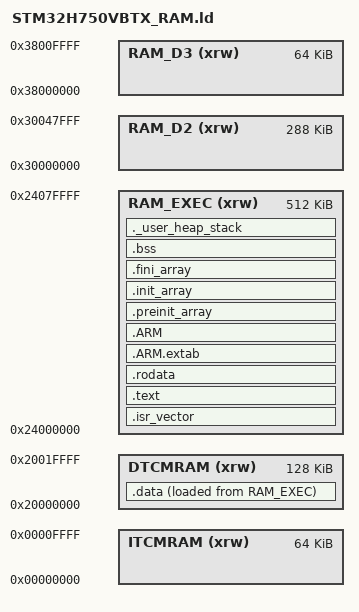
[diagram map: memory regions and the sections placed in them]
/*
 * Linker script that can be used to compile Glider fw so that it can be loaded
 * directly into STM32H750's RAM using ST-Link debugger/programmer device.
 *
 * First, use STM32Programmer with ST-Link to change the program start address
 * from 0x08000000 to 0x24000000.
 *
 * In Linux OpenOCD and GDB can be used to load firmware, set breakpoints and so
 * on. Start openocd:
 *
 * $ openocd -f interface/stlink-v2.cfg -f target/stm32h7x.cfg
 *
 * In another terminal attach GDB to be able to load/start/stop and examine the
 * code
 *
 * $ arm-none-eabi-gdb -ex 'target extended-remote :3333' fw/DebugRAM/glider_ec_rtos.elf
 *
 *
 * To just reload the firmware, it's faster to run just OpenOCD
 *
 * $ openocd -f interface/stlink.cfg -f target/stm32h7x.cfg -c "init; halt; load_image fw/DebugRAM/glider_ec_rtos.elf; reset halt; resume; exit"
 *
 */

/* Entry Point */
ENTRY(Reset_Handler)

/* Highest address of the user mode stack */
_estack = ORIGIN(RAM_EXEC) + LENGTH(RAM_EXEC);    /* end of RAM */
/* Generate a link error if heap and stack don't fit into RAM */
_Min_Heap_Size = 0x200;      /* required amount of heap  */
_Min_Stack_Size = 0x400; /* required amount of stack */

/* Specify the memory areas */
MEMORY
{
  RAM_EXEC (xrw)  : ORIGIN = 0x24000000, LENGTH = 512K
  DTCMRAM (xrw)   : ORIGIN = 0x20000000, LENGTH = 128K
  RAM_D2 (xrw)    : ORIGIN = 0x30000000, LENGTH = 288K
  RAM_D3 (xrw)    : ORIGIN = 0x38000000, LENGTH = 64K
  ITCMRAM (xrw)   : ORIGIN = 0x00000000, LENGTH = 64K
}

/* Define output sections */
SECTIONS
{
  /* The startup code goes first into RAM_EXEC */
  .isr_vector :
  {
    . = ALIGN(4);
    KEEP(*(.isr_vector)) /* Startup code */
    . = ALIGN(4);
  } >RAM_EXEC

  /* The program code and other data goes into RAM_EXEC */
  .text :
  {
    . = ALIGN(4);
    *(.text)           /* .text sections (code) */
    *(.text*)          /* .text* sections (code) */
    *(.glue_7)         /* glue arm to thumb code */
    *(.glue_7t)        /* glue thumb to arm code */
    *(.eh_frame)
    *(.RamFunc)        /* .RamFunc sections */
    *(.RamFunc*)       /* .RamFunc* sections */

    KEEP (*(.init))
    KEEP (*(.fini))

    . = ALIGN(4);
    _etext = .;        /* define a global symbols at end of code */
  } >RAM_EXEC

  /* Constant data goes into RAM_EXEC */
  .rodata :
  {
    . = ALIGN(4);
    *(.rodata)         /* .rodata sections (constants, strings, etc.) */
    *(.rodata*)        /* .rodata* sections (constants, strings, etc.) */
    . = ALIGN(4);
  } >RAM_EXEC

  .ARM.extab (READONLY) : /* The READONLY keyword is only supported in GCC11 and later, remove it if using GCC10 or earlier. */
  {
    *(.ARM.extab* .gnu.linkonce.armextab.*)
  } >RAM_EXEC
  .ARM (READONLY) : /* The READONLY keyword is only supported in GCC11 and later, remove it if using GCC10 or earlier. */
  {
    __exidx_start = .;
    *(.ARM.exidx*)
    __exidx_end = .;
  } >RAM_EXEC

  .preinit_array (READONLY) : /* The READONLY keyword is only supported in GCC11 and later, remove it if using GCC10 or earlier. */
  {
    PROVIDE_HIDDEN (__preinit_array_start = .);
    KEEP (*(.preinit_array*))
    PROVIDE_HIDDEN (__preinit_array_end = .);
  } >RAM_EXEC

  .init_array (READONLY) : /* The READONLY keyword is only supported in GCC11 and later, remove it if using GCC10 or earlier. */
  {
    PROVIDE_HIDDEN (__init_array_start = .);
    KEEP (*(SORT(.init_array.*)))
    KEEP (*(.init_array*))
    PROVIDE_HIDDEN (__init_array_end = .);
  } >RAM_EXEC

  .fini_array (READONLY) : /* The READONLY keyword is only supported in GCC11 and later, remove it if using GCC10 or earlier. */
  {
    PROVIDE_HIDDEN (__fini_array_start = .);
    KEEP (*(SORT(.fini_array.*)))
    KEEP (*(.fini_array*))
    PROVIDE_HIDDEN (__fini_array_end = .);
  } >RAM_EXEC

  /* used by the startup to initialize data */
  _sidata = LOADADDR(.data);

  /* Initialized data sections goes into RAM, load LMA copy after code */
  .data :
  {
    . = ALIGN(4);
    _sdata = .;        /* create a global symbol at data start */
    *(.data)           /* .data sections */
    *(.data*)          /* .data* sections */

    . = ALIGN(4);
    _edata = .;        /* define a global symbol at data end */
  } >DTCMRAM AT> RAM_EXEC
  /* } >DTCMRAM */

  /* Uninitialized data section */
  . = ALIGN(4);
  .bss :
  {
    /* This is used by the startup in order to initialize the .bss section */
    _sbss = .;         /* define a global symbol at bss start */
    __bss_start__ = _sbss;
    *(.bss)
    *(.bss*)
    *(COMMON)

    . = ALIGN(4);
    _ebss = .;         /* define a global symbol at bss end */
    __bss_end__ = _ebss;
  } >RAM_EXEC

  /* User_heap_stack section, used to check that there is enough RAM left */
  ._user_heap_stack :
  {
    . = ALIGN(8);
    PROVIDE ( end = . );
    PROVIDE ( _end = . );
    . = . + _Min_Heap_Size;
    . = . + _Min_Stack_Size;
    . = ALIGN(8);
  } >RAM_EXEC

  /* Remove information from the standard libraries */
  /DISCARD/ :
  {
    libc.a ( * )
    libm.a ( * )
    libgcc.a ( * )
  }

  .ARM.attributes 0 : { *(.ARM.attributes) }
}
